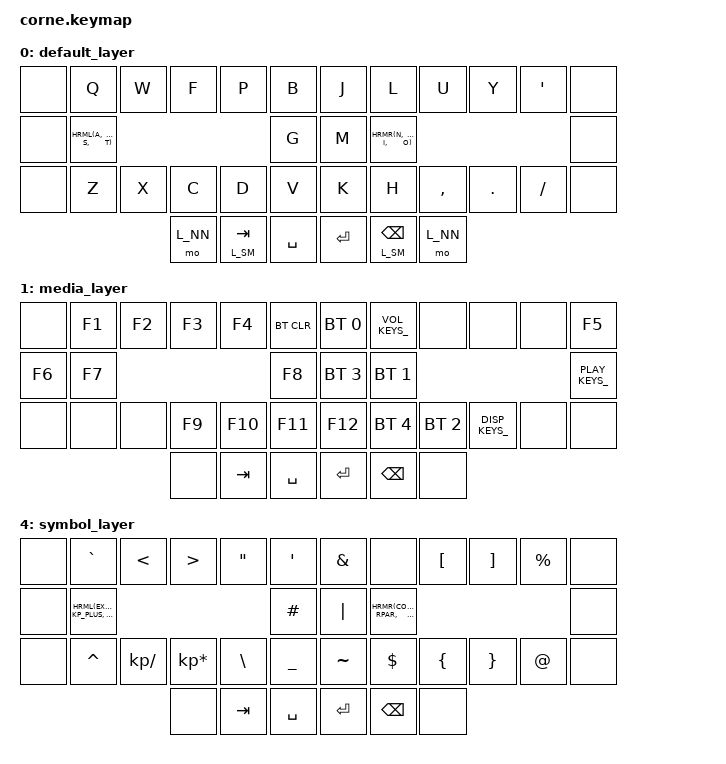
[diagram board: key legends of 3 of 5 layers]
/*
 * Copyright (c) 2020 The ZMK Contributors
 *
 * SPDX-License-Identifier: MIT
 */

#include <behaviors.dtsi>
#include <dt-bindings/zmk/keys.h>
#include <dt-bindings/zmk/bt.h>

#include "zmk-helpers/helper.h"
#include "zmk-helpers/key-labels/42.h"  // Must use Corne42 template because cornes are usually 6-column

// Alias
#define ___      &trans
#define _x_      &none

#define L_BS    0   // base
#define L_MD    1   // media
#define L_NM    2   // numpad right
#define L_NN    3   // num-nav
#define L_SM    4   // symbol

// Tapping Settings
#define QUICK_TAP_MS 175

&sk {  // sticky-key config
    release-after-ms = <900>;  // release after 0.6s
    quick-release;             // no double capitalization when rolling keys
};

&sl {  // sticky-layer config
    ignore-modifiers;          // allow chording sticky mods & layers
};

&lt {  // layer-tap config
    flavor = "balanced";
    tapping-term-ms = <200>;
    quick-tap-ms = <QUICK_TAP_MS>;
};

// Home Row Mods
#define HRML(k1, k2, k3, k4) &hml LSHFT k1 &hml LCTRL k2 &hml LALT  k3 &hml LGUI k4
#define HRMR(k1, k2, k3, k4) &hmr RGUI k1 &hmr RALT  k2 &hmr RCTRL k3 &hmr RSHFT k4

/* use helper macros to define left and right hand keys */
#define KEYS_L LT0 LT1 LT2 LT3 LT4 LM0 LM1 LM2 LM3 LM4 LB0 LB1 LB2 LB3 LB4  // left-hand keys
#define KEYS_R RT0 RT1 RT2 RT3 RT4 RM0 RM1 RM2 RM3 RM4 RB0 RB1 RB2 RB3 RB4  // right-hand keys
#define THUMBS LH2 LH1 LH0 RH0 RH1 RH2                                      // thumb keys

// Media Controls
#define _BT_SEL_KEYS_ &bt BT_SEL 0 &bt BT_SEL 1 &bt BT_SEL 2 &bt BT_SEL 3 &bt BT_CLR
#define _VOL_KEYS_ &kp C_VOL_DN &kp C_VOL_UP &kp C_MUTE
#define _PLAY_KEYS_ &kp C_PREV &kp C_PP &kp C_NEXT
#define _DISP_KEYS_ &kp C_BRI_DN &kp C_BRI_UP &kp PSCRN

/ {
        behaviors {
            hml: hml {
                compatible = "zmk,behavior-hold-tap";
                #binding-cells = <2>;
                flavor = "balanced";
                tapping-term-ms = <280>;
                quick-tap-ms = <QUICK_TAP_MS>;
                require-prior-idle-ms = <150>;
                bindings = <&kp>, <&kp>;
                hold-trigger-key-positions = <KEYS_R THUMBS>;
                hold-trigger-on-release;
            };
            hmr: hmr {
                compatible = "zmk,behavior-hold-tap";
                #binding-cells = <2>;
                flavor = "balanced";
                tapping-term-ms = <280>;
                quick-tap-ms = <QUICK_TAP_MS>;
                require-prior-idle-ms = <150>;
                bindings = <&kp>, <&kp>;
                hold-trigger-key-positions = <KEYS_L THUMBS>;
                hold-trigger-on-release;
            };
        };

        combos {
            compatible = "zmk,combos";

            combo_esc {
                timeout-ms = <50>;
                key-positions = <LT3 LT4>; // top left 2 keys
                bindings = <&kp ESCAPE>;
            };
            combo_semi {
                timeout-ms = <50>;
                key-positions = <RB2 RB3>;    // , .
                bindings = <&kp SEMI>;
            };
            combo_homel {
                timeout-ms = <100>;
                key-positions = <LM1 LM2 LM3>;    // left home row middle
                bindings = <&to L_BS>;
            };
            combo_homer {
                timeout-ms = <100>;
                key-positions = <RM1 RM2 RM3>;    // right home row middle
                bindings = <&to L_BS>;
            };
            combo_numpad {
                timeout-ms = <100>;
                key-positions = <RM0 RM1 RM2>;    // right home row in
                bindings = <&to L_NM>;
            };
            combo_numnav {
                timeout-ms = <100>;
                key-positions = <LM0 LM1 LM2>;    // left home row in
                bindings = <&to L_NN>;
            };
            combo_media {
                timeout-ms = <100>;
                key-positions = <LB1 LB2 LB3>;    // left bottom middle
                bindings = <&to L_MD>;
            };
            combo_capsword {
                timeout-ms = <50>;
                key-positions = <LM3 RM3>;
                bindings = <&caps_word>;
                layers = <0>;
            };
        };

        keymap {
            compatible = "zmk,keymap";

            default_layer { // layer 0 (defaultm coleman-dh w/ bspc del)
            bindings = <
//         ╭─────────────────────────────────────────────────╮   ╭─────────────────────────────────────────────────╮
//         │    Q    │    W    │    F    │    P    │    B    │   │    J    │    L    │    U    │    Y    │    '    │
    _x_     &kp Q     &kp W     &kp F     &kp P     &kp B         &kp J     &kp L     &kp U     &kp Y     &kp SQT       _x_ 
//         ├─────────┼─────────┼─────────┼─────────┼─────────┤   ├─────────┼─────────┼─────────┼─────────┼─────────┤
//         │    A    │    R    │    S    │    T    │    G    │   │    M    │    N    │    E    │    I    │    O    │
    _x_     HRML(A,       R,        S,        T)    &kp G         &kp M     HRMR(N,       E,        I,        O)        _x_ 
//         ├─────────┼─────────┼─────────┼─────────┼─────────┤   ├─────────┼─────────┼─────────┼─────────┼─────────┤
//         │    Z    │    X    │    C    │    D    │    V    │   │    K    │    H    │    ,    │    .    │    /    │
    _x_     &kp Z     &kp X     &kp C     &kp D     &kp V         &kp K     &kp H     &kp COMMA &kp DOT   &kp SLASH     _x_ 
//         ╰─────────┼─────────┼─────────┼─────────┼─────────┤   ├─────────┼─────────┼─────────┼─────────┼─────────╯
//                             │         │   TAB   │   SPC   │   │  ENTER  │   BSPC  │         │
                               &mo L_NN &lt L_SM TAB &kp SPACE   &kp RET  &lt L_SM BSPC &mo L_NN
//                             ╰─────────────────────────────╯   ╰─────────────────────────────╯
            >; // add TAB?? ***************
            };


            media_layer { // layer 1 
            bindings = <
//         ╭─────────────────────────────────────────────────╮   ╭─────────────────────────────────────────────────╮
//         │         │         │         │         │  BTCLR  │   │   BT0   │  VOL DN │ VOL UP  │  MUTE   │         │
    _x_     &kp F1    &kp F2    &kp F3    &kp F4    &bt BT_CLR    &bt BT_SEL 0        _VOL_KEYS_          &none         _x_ 
//         ├─────────┼─────────┼─────────┼─────────┼─────────┤   ├─────────┼─────────┼─────────┼─────────┼─────────┤
//         │         │         │         │         │   BT3   │   │   BT1   │   PREV  │  PL/PS  │  NEXT   │         │
    _x_     &kp F5    &kp F6    &kp F7    &kp F8    &bt BT_SEL 3  &bt BT_SEL 1       _PLAY_KEYS_          &none         _x_ 
//         ├─────────┼─────────┼─────────┼─────────┼─────────┤   ├─────────┼─────────┼─────────┼─────────┼─────────┤
//         │         │         │         │         │   BT4   │   │   BT2   │  BRI DN │ BRI UP  │  PSCRN  │         │
    _x_     &kp F9    &kp F10   &kp F11   &kp F12   &bt BT_SEL 4  &bt BT_SEL 2       _DISP_KEYS_          &none         _x_ 
//         ╰─────────┼─────────┼─────────┼─────────┼─────────┤   ├─────────┼─────────┼─────────┼─────────┼─────────╯
//                             │         │   TAB   │   SPC   │   │  ENTER  │   BSPC  │         │
                                &none     &kp TAB   &kp SPACE     &kp RET   &kp BSPC  &none
//                             ╰─────────────────────────────╯   ╰─────────────────────────────╯
            >;
            };

            numpad_layer {
            bindings = <
//         ╭─────────────────────────────────────────────────╮   ╭─────────────────────────────────────────────────╮
//         │    !    │    %    │    ^    │    <    │    >    │   │    7    │    8    │    9    │   BSPC  │    =    │
    _x_     &kp EXCL  &kp PRCNT &kp CARET &kp LT    &kp GT        &kp N7    &kp N8    &kp N9    &kp BSPC  &kp EQUAL         _x_ 
//         ├─────────┼─────────┼─────────┼─────────┼─────────┤   ├─────────┼─────────┼─────────┼─────────┼─────────┤
//         │    :    │    \    │    _    │    (    │    )    │   │    4    │    5    │    6    │    -    │    /    │
    _x_     &kp COLON &kp BSLH  &kp UNDER &kp LPAR  &kp RPAR      &kp N4    &kp N5    &kp N6  &kp KP_MINUS &kp KP_DIVIDE    _x_ 
//         ├─────────┼─────────┼─────────┼─────────┼─────────┤   ├─────────┼─────────┼─────────┼─────────┼─────────┤
//         │         │    {    │    }    │    [    │    ]    │   │    1    │    2    │    3    │    +    │    *    │
    _x_     &none     &kp LBRC  &kp RBRC  &kp LBKT  &kp RBKT      &kp N1    &kp N2    &kp N3  &kp KP_PLUS &kp KP_MULTIPLY   _x_ 
//         ╰─────────┼─────────┼─────────┼─────────┼─────────┤   ├─────────┼─────────┼─────────┼─────────┼─────────╯
//                             │  arrows │   TAB   │   SPC   │   │  ENTER  │    0    │    .    │
                                &mo L_NN  &kp TAB   &kp SPACE     &kp RET   &kp N0     &kp DOT
//                             ╰─────────────────────────────╯   ╰─────────────────────────────╯
            >;
            };
            
            numnav_layer {
            bindings = <
//         ╭─────────────────────────────────────────────────╮   ╭─────────────────────────────────────────────────╮
//         │    !    │    %    │    7    │    8    │    9    │   │   HOME  │         │    ^    │         │  PG_UP  │
    _x_     &kp EXCL  &kp PRCNT &kp N7    &kp N8    &kp N9        &kp HOME  &none     &kp UP    &none     &kp PG_UP     _x_ 
//         ├─────────┼─────────┼─────────┼─────────┼─────────┤   ├─────────┼─────────┼─────────┼─────────┼─────────┤
//         │    -    │    /    │    4    │    5    │    6    │   │   END   │    <-   │    V    │    ->   │  PG_DN  │
    _x_     HRML(KP_MINUS, BSLH,   N4,       N5)    &kp N6        &kp END   &kp LEFT  &kp DOWN  &kp RIGHT &kp PG_DN     _x_ 
//         ├─────────┼─────────┼─────────┼─────────┼─────────┤   ├─────────┼─────────┼─────────┼─────────┼─────────┤
//         │    +    │    *    │    1    │    2    │    3    │   │         │         │         │         │         │
_x_  &kp KP_PLUS &kp KP_MULTIPLY &kp N1   &kp N2    &kp N3        &none     &kp RGUI  &kp RALT  &kp RCTRL &kp RSHFT     _x_ 
//         ╰─────────┼─────────┼─────────┼─────────┼─────────┤   ├─────────┼─────────┼─────────┼─────────┼─────────╯
//                             │    0    │    .    │   SPC   │   │  ENTER  │   BSPC  │   NONE  │
                                &kp N0    &kp DOT   &kp SPACE     &kp RET   &kp BSPC  &none
//                             ╰─────────────────────────────╯   ╰─────────────────────────────╯
            >;
            };

            symbol_layer { // layer 0 (defaultm coleman-dh w/ bspc del)
            bindings = <
//         ╭─────────────────────────────────────────────────╮   ╭─────────────────────────────────────────────────╮
//         │    `    │    <    │    >    │    "    │    '    │   │    &    │         │    [    │    ]    │    %    │
    _x_     &kp GRAVE &kp LT    &kp GT    &kp DQT   &kp SQT       &kp AMPS  &none     &kp LBKT  &kp RBKT  &kp PRCNT     _x_ 
//         ├─────────┼─────────┼─────────┼─────────┼─────────┤   ├─────────┼─────────┼─────────┼─────────┼─────────┤
//         │    !    │    -    │    +    │    =    │    #    │   │    |    │    :    │    (    │    )    │    ?    │
    _x_     HRML(EXCL, KP_MINUS, KP_PLUS,   EQUAL)  &kp HASH      &kp PIPE  HRMR(COLON,  LPAR,    RPAR,     QMARK)      _x_ 
//         ├─────────┼─────────┼─────────┼─────────┼─────────┤   ├─────────┼─────────┼─────────┼─────────┼─────────┤
//         │    ^    │    /    │    *    │    \    │    _    │   │    ~    │    $    │    {    │    }    │    @    │
 _x_ &kp CARET &kp KP_DIVIDE &kp KP_MULTIPLY &kp BSLH &kp UNDER   &kp TILDE &kp DLLR  &kp LBRC  &kp RBRC  &kp AT        _x_ 
//         ╰─────────┼─────────┼─────────┼─────────┼─────────┤   ├─────────┼─────────┼─────────┼─────────┼─────────╯
//                             │         │   TAB   │   SPC   │   │  ENTER  │  BSPC   │         │
                                &none     &kp TAB   &kp SPACE     &kp RET   &kp BSPC  &none
//                             ╰─────────────────────────────╯   ╰─────────────────────────────╯
            >;
            };

        };
};
